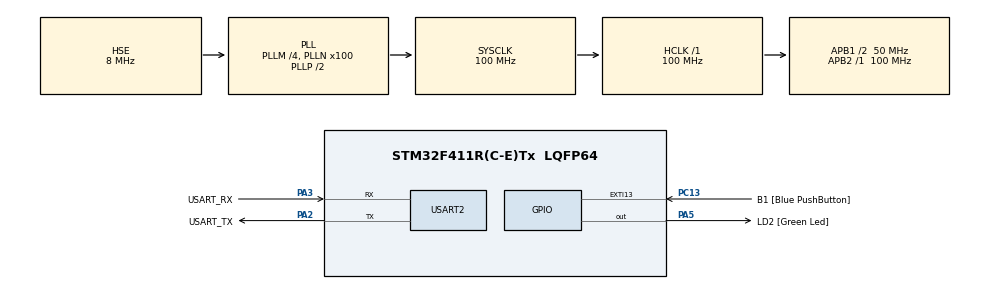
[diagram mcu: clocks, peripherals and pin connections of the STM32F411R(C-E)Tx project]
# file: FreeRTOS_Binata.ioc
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Dma.Request0=USART2_TX
Dma.Request1=USART2_RX
Dma.USART2_RX.1.Direction=DMA_PERIPH_TO_MEMORY
Dma.USART2_RX.1.FIFOMode=DMA_FIFOMODE_DISABLE
Dma.USART2_RX.1.Instance=DMA1_Stream5
Dma.USART2_RX.1.MemDataAlignment=DMA_MDATAALIGN_BYTE
Dma.USART2_RX.1.MemInc=DMA_MINC_ENABLE
Dma.USART2_RX.1.Mode=DMA_CIRCULAR
Dma.USART2_RX.1.PeriphDataAlignment=DMA_PDATAALIGN_BYTE
Dma.USART2_RX.1.PeriphInc=DMA_PINC_DISABLE
Dma.USART2_RX.1.Priority=DMA_PRIORITY_LOW
Dma.USART2_TX.0.Direction=DMA_MEMORY_TO_PERIPH
Dma.USART2_TX.0.FIFOMode=DMA_FIFOMODE_DISABLE
Dma.USART2_TX.0.Instance=DMA1_Stream6
Dma.USART2_TX.0.MemDataAlignment=DMA_MDATAALIGN_BYTE
Dma.USART2_TX.0.MemInc=DMA_MINC_ENABLE
Dma.USART2_TX.0.Mode=DMA_NORMAL
Dma.USART2_TX.0.PeriphDataAlignment=DMA_PDATAALIGN_BYTE
Dma.USART2_TX.0.PeriphInc=DMA_PINC_DISABLE
Dma.USART2_TX.0.Priority=DMA_PRIORITY_LOW
FREERTOS.BinarySemaphores01=usartTxDoneSem,Dynamic,NULL,Available
FREERTOS.Queues01=usartTxQueue,16,uint32_t,0,Dynamic,NULL,NULL
FREERTOS.Tasks01=defaultTask,24,128,StartDefaultTask,Default,NULL,Dynamic,NULL,NULL;cmdParserTask,24,512,StartCmdParserTask,As external,NULL,Dynamic,NULL,NULL;usartSendTask,24,256,StartUsartSendTask,As external,NULL,Dynamic,NULL,NULL;producerTask1,24,128,StartProducerTask1,As external,NULL,Dynamic,NULL,NULL;producerTask2,24,128,StartProducerTask2,As external,NULL,Dynamic,NULL,NULL
FREERTOS.configUSE_NEWLIB_REENTRANT=1
FREERTOS.configUSE_STATS_FORMATTING_FUNCTIONS=1
Mcu.Family=STM32F4
Mcu.Name=STM32F411R(C-E)Tx
Mcu.Package=LQFP64
NVIC.DMA1_Stream5_IRQn=true\:5\:0\:false\:false\:true\:true\:false\:true\:true
NVIC.DMA1_Stream6_IRQn=true\:5\:0\:false\:false\:true\:true\:false\:true\:true
NVIC.PriorityGroup=NVIC_PRIORITYGROUP_4
NVIC.TIM1_BRK_TIM9_IRQn=true\:15\:0\:false\:false\:true\:false\:false\:true\:true
NVIC.TimeBase=TIM1_BRK_TIM9_IRQn
NVIC.TimeBaseIP=TIM9
NVIC.USART2_IRQn=true\:5\:0\:false\:false\:true\:true\:true\:true\:true
PA13.GPIO_Label=TMS
PA13.Mode=Serial_Wire
PA13.Signal=SYS_JTMS-SWDIO
PA14.GPIO_Label=TCK
PA14.Mode=Serial_Wire
PA14.Signal=SYS_JTCK-SWCLK
PA2.GPIO_Label=USART_TX
PA2.Mode=Asynchronous
PA2.Signal=USART2_TX
PA3.GPIO_Label=USART_RX
PA3.Mode=Asynchronous
PA3.Signal=USART2_RX
PA5.GPIO_Label=LD2 [Green Led]
PA5.Signal=GPIO_Output
PB3.GPIO_Label=SWO
PB3.Signal=SYS_JTDO-SWO
PC13-ANTI_TAMP.GPIO_Label=B1 [Blue PushButton]
PC13-ANTI_TAMP.GPIO_ModeDefaultEXTI=GPIO_MODE_IT_FALLING
PC13-ANTI_TAMP.Signal=GPXTI13
PC14-OSC32_IN.Mode=LSE-External-Oscillator
PC14-OSC32_IN.Signal=RCC_OSC32_IN
PC15-OSC32_OUT.Mode=LSE-External-Oscillator
PC15-OSC32_OUT.Signal=RCC_OSC32_OUT
PH0\ -\ OSC_IN.Mode=HSE-External-Clock-Source
PH0\ -\ OSC_IN.Signal=RCC_OSC_IN
PH1\ -\ OSC_OUT.Mode=HSE-External-Clock-Source
PH1\ -\ OSC_OUT.Signal=RCC_OSC_OUT
ProjectManager.HeapSize=0x200
ProjectManager.StackSize=0x400
ProjectManager.TargetToolchain=STM32CubeIDE
RCC.48MHZClocksFreq_Value=50000000
RCC.AHBFreq_Value=100000000
RCC.APB1CLKDivider=RCC_HCLK_DIV2
RCC.APB1Freq_Value=50000000
RCC.APB1TimFreq_Value=100000000
RCC.APB2Freq_Value=100000000
RCC.APB2TimFreq_Value=100000000
RCC.CortexFreq_Value=100000000
RCC.FLatency-AdvancedSettings=FLASH_LATENCY_3
RCC.HCLKFreq_Value=100000000
RCC.HSE_VALUE=8000000
RCC.HSI_VALUE=16000000
RCC.PLLM=4
RCC.PLLN=100
RCC.PLLSourceVirtual=RCC_PLLSOURCE_HSE
RCC.SYSCLKFreq_VALUE=100000000
RCC.SYSCLKSource=RCC_SYSCLKSOURCE_PLLCLK
RCC.VCOOutputFreq_Value=200000000
USART2.VirtualMode=VM_ASYNC
VP_FREERTOS_VS_CMSIS_V2.Mode=CMSIS_V2
VP_SYS_VS_tim9.Mode=TIM9
board=NUCLEO-F411RE

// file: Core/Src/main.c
/* USER CODE BEGIN Header */
/**
  ******************************************************************************
  * @file           : main.c
  * @brief          : Main program body
  ******************************************************************************
  * @attention
  *
  * Copyright (c) 2025 STMicroelectronics.
  * All rights reserved.
  *
  * This software is licensed under terms that can be found in the LICENSE file
  * in the root directory of this software component.
  * If no LICENSE file comes with this software, it is provided AS-IS.
  *
  ******************************************************************************
  */
/* USER CODE END Header */
#include "main.h"
#include "cmsis_os.h"
#include "dma.h"
#include "usart.h"
#include "gpio.h"

void SystemClock_Config(void);
void MX_FREERTOS_Init(void);

int main(void)
{

  /* MCU Configuration--------------------------------------------------------*/

  /* Reset of all peripherals, Initializes the Flash interface and the Systick. */
  HAL_Init();

  /* Configure the system clock */
  SystemClock_Config();

  /* Initialize all configured peripherals */
  MX_GPIO_Init();
  MX_DMA_Init();
  MX_USART2_UART_Init();

  /* Init scheduler */
  osKernelInitialize();

  /* Call init function for freertos objects (in cmsis_os2.c) */
  MX_FREERTOS_Init();

  /* Start scheduler */
  osKernelStart();

  /* We should never get here as control is now taken by the scheduler */

  /* Infinite loop */
  while (1)
  {

  }
}

void SystemClock_Config(void)
{
  RCC_OscInitTypeDef RCC_OscInitStruct = {0};
  RCC_ClkInitTypeDef RCC_ClkInitStruct = {0};

  /** Configure the main internal regulator output voltage
  */
  __HAL_RCC_PWR_CLK_ENABLE();
  __HAL_PWR_VOLTAGESCALING_CONFIG(PWR_REGULATOR_VOLTAGE_SCALE1);

  /** Initializes the RCC Oscillators according to the specified parameters
  * in the RCC_OscInitTypeDef structure.
  */
  RCC_OscInitStruct.OscillatorType = RCC_OSCILLATORTYPE_HSE;
  RCC_OscInitStruct.HSEState = RCC_HSE_BYPASS;
  RCC_OscInitStruct.PLL.PLLState = RCC_PLL_ON;
  RCC_OscInitStruct.PLL.PLLSource = RCC_PLLSOURCE_HSE;
  RCC_OscInitStruct.PLL.PLLM = 4;
  RCC_OscInitStruct.PLL.PLLN = 100;
  RCC_OscInitStruct.PLL.PLLP = RCC_PLLP_DIV2;
  RCC_OscInitStruct.PLL.PLLQ = 4;
  if (HAL_RCC_OscConfig(&RCC_OscInitStruct) != HAL_OK)
  {
    Error_Handler();
  }

  /** Initializes the CPU, AHB and APB buses clocks
  */
  RCC_ClkInitStruct.ClockType = RCC_CLOCKTYPE_HCLK|RCC_CLOCKTYPE_SYSCLK
                              |RCC_CLOCKTYPE_PCLK1|RCC_CLOCKTYPE_PCLK2;
  RCC_ClkInitStruct.SYSCLKSource = RCC_SYSCLKSOURCE_PLLCLK;
  RCC_ClkInitStruct.AHBCLKDivider = RCC_SYSCLK_DIV1;
  RCC_ClkInitStruct.APB1CLKDivider = RCC_HCLK_DIV2;
  RCC_ClkInitStruct.APB2CLKDivider = RCC_HCLK_DIV1;

  if (HAL_RCC_ClockConfig(&RCC_ClkInitStruct, FLASH_LATENCY_3) != HAL_OK)
  {
    Error_Handler();
  }
}

void HAL_TIM_PeriodElapsedCallback(TIM_HandleTypeDef *htim)
{
  if (htim->Instance == TIM9)
  {
    HAL_IncTick();
  }
}

void Error_Handler(void)
{
  __disable_irq();
  while (1)
  {
  }
}

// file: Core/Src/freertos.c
/* USER CODE BEGIN Header */
/**
  ******************************************************************************
  * File Name          : freertos.c
  * Description        : Code for freertos applications
  ******************************************************************************
  * @attention
  *
  * Copyright (c) 2025 STMicroelectronics.
  * All rights reserved.
  *
  * This software is licensed under terms that can be found in the LICENSE file
  * in the root directory of this software component.
  * If no LICENSE file comes with this software, it is provided AS-IS.
  *
  ******************************************************************************
  */
/* USER CODE END Header */

#include "FreeRTOS.h"
#include "task.h"
#include "main.h"
#include "cmsis_os.h"

/* USER CODE BEGIN Includes */
#include "app_main.h"
#include "cli_commands.h"
/* USER CODE END Includes */

/* Definitions for defaultTask */
osThreadId_t defaultTaskHandle;
const osThreadAttr_t defaultTask_attributes = {
  .name = "defaultTask",
  .stack_size = 128 * 4,
  .priority = (osPriority_t) osPriorityNormal,
};
/* Definitions for cmdParserTask */
osThreadId_t cmdParserTaskHandle;
const osThreadAttr_t cmdParserTask_attributes = {
  .name = "cmdParserTask",
  .stack_size = 512 * 4,
  .priority = (osPriority_t) osPriorityNormal,
};
/* Definitions for usartSendTask */
osThreadId_t usartSendTaskHandle;
const osThreadAttr_t usartSendTask_attributes = {
  .name = "usartSendTask",
  .stack_size = 256 * 4,
  .priority = (osPriority_t) osPriorityNormal,
};
/* Definitions for producerTask1 */
osThreadId_t producerTask1Handle;
const osThreadAttr_t producerTask1_attributes = {
  .name = "producerTask1",
  .stack_size = 128 * 4,
  .priority = (osPriority_t) osPriorityNormal,
};
/* Definitions for producerTask2 */
osThreadId_t producerTask2Handle;
const osThreadAttr_t producerTask2_attributes = {
  .name = "producerTask2",
  .stack_size = 128 * 4,
  .priority = (osPriority_t) osPriorityNormal,
};
/* Definitions for usartTxQueue */
osMessageQueueId_t usartTxQueueHandle;
const osMessageQueueAttr_t usartTxQueue_attributes = {
  .name = "usartTxQueue"
};
/* Definitions for usartTxDoneSem */
osSemaphoreId_t usartTxDoneSemHandle;
const osSemaphoreAttr_t usartTxDoneSem_attributes = {
  .name = "usartTxDoneSem"
};

void StartDefaultTask(void *argument);
extern void StartCmdParserTask(void *argument);
extern void StartUsartSendTask(void *argument);
extern void StartProducerTask1(void *argument);
extern void StartProducerTask2(void *argument);

void MX_FREERTOS_Init(void); /* (MISRA C 2004 rule 8.1) */

void MX_FREERTOS_Init(void) {
  /* USER CODE BEGIN Init */
	app_main_init();
	vRegisterCLICommands(); // Call the registration function here
  /* USER CODE END Init */

  /* Create the semaphores(s) */
  /* creation of usartTxDoneSem */
  usartTxDoneSemHandle = osSemaphoreNew(1, 1, &usartTxDoneSem_attributes);

  /* Create the queue(s) */
  /* creation of usartTxQueue */
  usartTxQueueHandle = osMessageQueueNew (16, sizeof(uint32_t), &usartTxQueue_attributes);

  /* Create the thread(s) */
  /* creation of defaultTask */
  defaultTaskHandle = osThreadNew(StartDefaultTask, NULL, &defaultTask_attributes);

  /* creation of cmdParserTask */
  cmdParserTaskHandle = osThreadNew(StartCmdParserTask, NULL, &cmdParserTask_attributes);

  /* creation of usartSendTask */
  usartSendTaskHandle = osThreadNew(StartUsartSendTask, NULL, &usartSendTask_attributes);

  /* creation of producerTask1 */
  producerTask1Handle = osThreadNew(StartProducerTask1, NULL, &producerTask1_attributes);

  /* creation of producerTask2 */
  producerTask2Handle = osThreadNew(StartProducerTask2, NULL, &producerTask2_attributes);

}

void StartDefaultTask(void *argument)
{
  /* USER CODE BEGIN StartDefaultTask */
	app_main();

  /* Infinite loop */
  for(;;)
  {
    osDelay(1);
  }
  /* USER CODE END StartDefaultTask */
}
